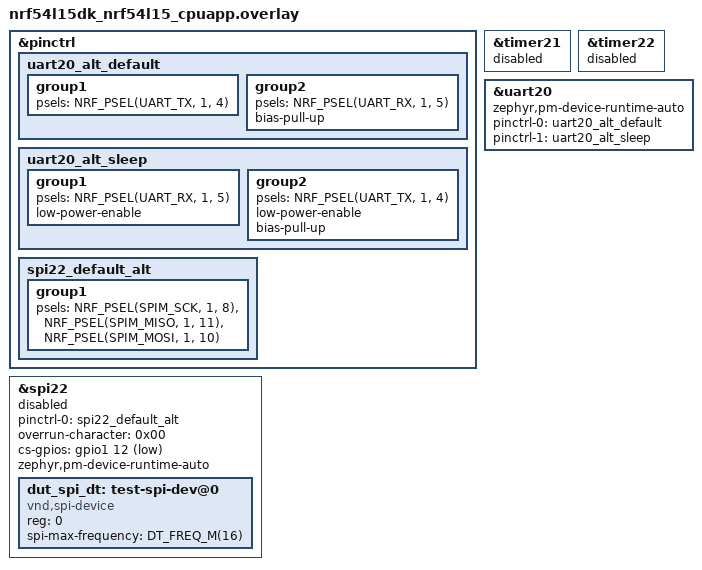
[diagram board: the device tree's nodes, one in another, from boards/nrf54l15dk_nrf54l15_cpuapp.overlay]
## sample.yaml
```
sample:
  description: Sample showing PPI sequencer
  name: PPI sequencer sample
tests:
  sample.peripheral.ppi_seq:
    sysbuild: true
    build_only: true
    integration_platforms:
      - nrf54l15dk/nrf54l15/cpuapp
    platform_allow:
      - nrf54l15dk/nrf54l15/cpuapp
```

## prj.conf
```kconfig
CONFIG_NRF_SYS_EVENT=y
CONFIG_PPI_SEQ=y
CONFIG_NRFX_SPIM=y
CONFIG_NRFX_SAADC=y
CONFIG_SHELL=y
CONFIG_CPU_LOAD=y
CONFIG_HEAP_MEM_POOL_SIZE=4096

CONFIG_PM_DEVICE=y
CONFIG_PM_DEVICE_RUNTIME=y
CONFIG_LOG=n

CONFIG_PPI_TRACE=y
```

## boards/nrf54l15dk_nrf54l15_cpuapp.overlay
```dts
/*
 * Copyright (c) 2024 Nordic Semiconductor
 *
 * SPDX-License-Identifier: Apache-2.0
 */

&pinctrl {
	uart20_alt_default: uart20_alt_default {
		group1 {
			psels = <NRF_PSEL(UART_TX, 1, 4)>;
		};

		group2 {
			psels = <NRF_PSEL(UART_RX, 1, 5)>;
			bias-pull-up;
		};
	};

	uart20_alt_sleep: uart20_alt_sleep {
		group1 {
			psels = <NRF_PSEL(UART_RX, 1, 5)>;
			low-power-enable;
		};

		group2 {
			psels = <NRF_PSEL(UART_TX, 1, 4)>;
			low-power-enable;
			bias-pull-up;
		};
	};

	spi22_default_alt: spi22_default_alt {
		group1 {
			psels = <NRF_PSEL(SPIM_SCK, 1, 8)>,
				<NRF_PSEL(SPIM_MISO, 1, 11)>,
				<NRF_PSEL(SPIM_MOSI, 1, 10)>;
		};
	};
};

cnt_timer: &timer21 {
	status = "reserved";
};

trig_timer: &timer22 {
	status = "reserved";
};

sample_spi: &spi22 {
	status = "reserved";
	pinctrl-0 = <&spi22_default_alt>;
	pinctrl-names = "default";
	overrun-character = <0x00>;
	cs-gpios = <&gpio1 12 GPIO_ACTIVE_LOW>;
	zephyr,pm-device-runtime-auto;

	dut_spi_dt: test-spi-dev@0 {
		compatible = "vnd,spi-device";
		reg = <0>;
		spi-max-frequency = <DT_FREQ_M(16)>;
	};
};

&uart20 {
	zephyr,pm-device-runtime-auto;
	pinctrl-0 = <&uart20_alt_default>;
	pinctrl-1 = <&uart20_alt_sleep>;
};
```

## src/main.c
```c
/*
 * Copyright (c) 2025 Nordic Semiconductor ASA
 *
 * SPDX-License-Identifier: LicenseRef-Nordic-5-Clause
 */

#include "common.h"
#include <string.h>
#include <stdlib.h>
#include <zephyr/kernel.h>
#include <zephyr/shell/shell.h>
#include <zephyr/pm/device.h>
#include <zephyr/pm/device_runtime.h>
#include <zephyr/logging/log.h>
LOG_MODULE_REGISTER(ppi_seq);

struct ppi_seq_generic_config current_config = {
	.mode = PPI_SEQ_SAMPLE_GRTC,
	.notifier = PPI_SEQ_NOTIFIER_SYS_TIMER,
	.period = 1000,
	.batch_cnt = 16,
	.repeat = 4,
};

int stop_shell_uart(const struct shell *sh)
{
	static const struct device *uart = DEVICE_DT_GET(DT_CHOSEN(zephyr_shell_uart));
	int pm_cnt = 0;
	int rv;

	if (IS_ENABLED(CONFIG_PM_DEVICE_RUNTIME)) {
		enum pm_device_state state;

		/* Disable UART to reduce the current consumption. */
		do {
			rv = pm_device_state_get(uart, &state);
			if (rv < 0) {
				return rv;
			}
			if (state != PM_DEVICE_STATE_ACTIVE) {
				break;
			}
			pm_device_runtime_put(uart);
			pm_cnt++;
		} while (1);
	}

	return pm_cnt;
}

void restart_shell_uart(const struct shell *sh, int pm_cnt)
{
	static const struct device *uart = DEVICE_DT_GET(DT_CHOSEN(zephyr_shell_uart));

	if (IS_ENABLED(CONFIG_PM_DEVICE_RUNTIME)) {
		for (int i = 0; i < pm_cnt; i++) {
			pm_device_runtime_get(uart);
		}
	}
}

void print_generic_status(const struct shell *sh)
{
	shell_print(sh, "Current configuration:");
	shell_print(sh, "\tPeriod source method: %s",
		current_config.mode == PPI_SEQ_SAMPLE_RTC ? "RTC" :
		current_config.mode == PPI_SEQ_SAMPLE_GRTC ? "GRTC" : "TIMER");
	shell_print(sh, "\tBatch notifier: %s",
		current_config.notifier == PPI_SEQ_NOTIFIER_NRFX_TIMER ?
		"nrfx_timer" : "k_timer");
	shell_print(sh, "\tPeriod: %d us", current_config.period);
	shell_print(sh, "\tBatch count: %d", current_config.batch_cnt);
	shell_print(sh, "\tNumber of batches in the sequence: %d", current_config.repeat);
}

static int ppi_seq_status_handler(const struct shell *sh, size_t argc, char **argv)
{
	ARG_UNUSED(argc);
	ARG_UNUSED(argv);

	print_generic_status(sh);
	return 0;
}

static int config_mode_grtc_handler(const struct shell *sh, size_t argc, char **argv)
{
	ARG_UNUSED(argc);
	ARG_UNUSED(argv);
	ARG_UNUSED(sh);
	current_config.mode = PPI_SEQ_SAMPLE_GRTC;
	return 0;
}

static int config_mode_rtc_handler(const struct shell *sh, size_t argc, char **argv)
{
	ARG_UNUSED(argc);
	ARG_UNUSED(argv);
	ARG_UNUSED(sh);
	current_config.mode = PPI_SEQ_SAMPLE_RTC;
	return 0;
}

static int config_mode_timer_handler(const struct shell *sh, size_t argc, char **argv)
{
	ARG_UNUSED(argc);
	ARG_UNUSED(argv);
	ARG_UNUSED(sh);
	current_config.mode = PPI_SEQ_SAMPLE_TIMER;
	return 0;
}

static int config_notifier_k_timer_handler(const struct shell *sh, size_t argc, char **argv)
{
	ARG_UNUSED(argc);
	ARG_UNUSED(argv);
	ARG_UNUSED(sh);
	current_config.notifier = PPI_SEQ_NOTIFIER_SYS_TIMER;
	return 0;
}

static int config_notifier_nrfx_timer_handler(const struct shell *sh, size_t argc, char **argv)
{
	ARG_UNUSED(argc);
	ARG_UNUSED(argv);
	ARG_UNUSED(sh);
	current_config.notifier = PPI_SEQ_NOTIFIER_NRFX_TIMER;
	return 0;
}

static int config_period_handler(const struct shell *sh, size_t argc, char **argv)
{
	ARG_UNUSED(argc);
	ARG_UNUSED(sh);
	int rv = 0;

	current_config.period = shell_strtoul(argv[1], 0, &rv);

	return rv;
}

static int config_batch_handler(const struct shell *sh, size_t argc, char **argv)
{
	ARG_UNUSED(argc);
	ARG_UNUSED(sh);
	int rv = 0;

	current_config.batch_cnt = shell_strtoul(argv[1], 0, &rv);

	return rv;
}

static int config_repeat_handler(const struct shell *sh, size_t argc, char **argv)
{
	ARG_UNUSED(argc);
	ARG_UNUSED(sh);
	int rv = 0;

	current_config.repeat = shell_strtoul(argv[1], 0, &rv);

	return rv;
}

struct ppi_seq_generic_config *get_generic_config(void)
{
	return &current_config;
}

SHELL_SUBCMD_ADD((ppi_sequence, config), repeat, NULL, "Number of batches in the sequence",
		config_repeat_handler, 2, 0);
SHELL_SUBCMD_ADD((ppi_sequence, config), batch_count, NULL, "Number of periods in a batch",
		config_batch_handler, 2, 0);
SHELL_SUBCMD_ADD((ppi_sequence, config), period, NULL, "Period (in microseconds)",
		config_period_handler, 2, 0);

SHELL_SUBCMD_ADD((ppi_sequence, config, notifier), k_timer, NULL,
		"Configure k_timer notifier\n", config_notifier_k_timer_handler, 1, 0);
SHELL_SUBCMD_ADD((ppi_sequence, config, notifier), nrfx_timer, NULL,
		"Configure nrfx_timer notifier\n", config_notifier_nrfx_timer_handler, 1, 0);
SHELL_SUBCMD_SET_CREATE(config_notifier_cmd, (ppi_sequence, config, notifier));
SHELL_SUBCMD_ADD((ppi_sequence, config), notifier, &config_notifier_cmd, "Notifier method",
		NULL, 1, 0);

SHELL_SUBCMD_ADD((ppi_sequence, config, mode), grtc, NULL,
		"Configure RTC mode\n", config_mode_grtc_handler, 1, 0);
SHELL_SUBCMD_ADD((ppi_sequence, config, mode), rtc, NULL,
		"Configure RTC mode\n", config_mode_rtc_handler, 1, 0);
SHELL_SUBCMD_ADD((ppi_sequence, config, mode), timer, NULL,
		"Configure TIMER mode\n", config_mode_timer_handler, 1, 0);
SHELL_SUBCMD_SET_CREATE(config_mode_cmd, (ppi_sequence, config, mode));
SHELL_SUBCMD_ADD((ppi_sequence, config), mode, &config_mode_cmd, "Peripheral used for period",
		NULL, 1, 0);
SHELL_SUBCMD_SET_CREATE(config_cmds, (ppi_sequence, config));
SHELL_SUBCMD_ADD((ppi_sequence), config, &config_cmds,
		"Print configuration (no arguments) or configure specific parameter",
		ppi_seq_status_handler, 1, 0);
SHELL_SUBCMD_SET_CREATE(ppi_sequence_cmd, (ppi_sequence));
SHELL_CMD_REGISTER(ppi_sequence, &ppi_sequence_cmd,
		   "SPI/SAADC operations using software and PPI sequencer", NULL);

int main(void)
{
	printk("PPI Sequencer for SPI transfers\n");

	DBG_PIN_CFG();

	return 0;
}
```

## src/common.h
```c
/*
 * Copyright (c) 2025 Nordic Semiconductor ASA
 *
 * SPDX-License-Identifier: LicenseRef-Nordic-5-Clause
 */

#ifndef COMMON_H__
#define COMMON_H__

#include <hal/nrf_gpio.h>
#include <drivers/ppi_seq.h>
#include <zephyr/shell/shell.h>
#include <zephyr/debug/cpu_load.h>
#include <zephyr/logging/log.h>

#ifdef __cplusplus
extern "C" {
#endif

#define USE_DBG_PIN 1

#if USE_DBG_PIN
#define DBG_PIN (2 * 32 + 10)
#define DBG_PIN_TOGGLE() do { \
	nrf_gpio_pin_set(DBG_PIN); \
	k_busy_wait(10); \
	nrf_gpio_pin_clear(DBG_PIN); \
} while (0)

#define DBG_PIN_CFG() nrf_gpio_cfg_output(DBG_PIN)
#else
#define DBG_PIN_TOGGLE()
#define DBG_PIN_CFG()
#endif

enum ppi_seq_sample_mode {
	PPI_SEQ_SAMPLE_GRTC,
	PPI_SEQ_SAMPLE_RTC,
	PPI_SEQ_SAMPLE_TIMER,
};

struct ppi_seq_generic_config {
	enum ppi_seq_sample_mode mode;
	enum ppi_seq_notifier_type notifier;
	uint32_t period;
	uint32_t repeat;
	uint32_t batch_cnt;
};

int stop_shell_uart(const struct shell *sh);
void restart_shell_uart(const struct shell *sh, int pm_cnt);
struct ppi_seq_generic_config *get_generic_config(void);
void print_generic_status(const struct shell *sh);

#ifdef __cplusplus
}
#endif


#endif /* COMMON_H__ */
```

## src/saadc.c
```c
/*
 * Copyright (c) 2025 Nordic Semiconductor ASA
 *
 * SPDX-License-Identifier: LicenseRef-Nordic-5-Clause
 */

#include "common.h"
#include <errno.h>
#include <string.h>
#include <stdlib.h>
#include <zephyr/kernel.h>
#include <zephyr/drivers/pinctrl.h>
#include <nrfx_gpiote.h>
#include <nrfx_saadc.h>
#include <zephyr/drivers/gpio/gpio_nrf.h>
LOG_MODULE_DECLARE(ppi_seq);

#define SAADC_NODE DT_NODELABEL(adc)

static NRF_TIMER_Type *trig_timer = (NRF_TIMER_Type *)DT_REG_ADDR(DT_NODELABEL(trig_timer));
#ifdef CONFIG_SOC_NRF54L15_CPUAPP
static const void *rtc_reg = (void *)0x50105000;
#endif

static struct k_sem sem;
static uint32_t repeat_cnt;
static uint32_t buf_idx;
static nrf_saadc_value_t *manual_buffers[2];
static struct ppi_seq seq;
static struct ppi_seq_config seq_config;
static struct ppi_seq_notifier notifier;

static struct ppi_seq_generic_config *curr_cfg;

static int saadc_init(void)
{
	IRQ_CONNECT(DT_IRQN(SAADC_NODE), DT_IRQ_BY_IDX(SAADC_NODE, 0, priority),
			nrfx_saadc_irq_handler, NULL, 0);

	return nrfx_saadc_init(0);
}

static void saadc_uninit(uint32_t ch_mask)
{
	nrfx_saadc_channels_deconfig(ch_mask);
	nrfx_saadc_uninit();
}

static void saadc_event_handler(nrfx_saadc_evt_t const *event)
{
	int rv;

	switch (event->type) {
	case NRFX_SAADC_EVT_DONE:
		repeat_cnt--;
		break;
	case NRFX_SAADC_EVT_FINISHED:
		k_sem_give(&sem);
		break;
	case NRFX_SAADC_EVT_BUF_REQ:
		if (repeat_cnt > 1) {
			rv = nrfx_saadc_buffer_set(manual_buffers[buf_idx], curr_cfg->batch_cnt);
			buf_idx = buf_idx == 0 ? 1 : 0;
		}
		break;
	default:
		break;
	}
}

static int manual_run(const struct shell *sh, struct ppi_seq_generic_config *config, int *load)
{
	int rv;
	nrfx_saadc_channel_t channel_config =
		NRFX_SAADC_DEFAULT_CHANNEL_SE(NRFX_ANALOG_EXTERNAL_AIN4, 0);
	uint32_t total = config->batch_cnt * config->repeat * config->period;
	nrfx_saadc_adv_config_t saadc_config = {
		.oversampling = NRF_SAADC_OVERSAMPLE_DISABLED,
		.burst = NRF_SAADC_BURST_DISABLED,
		.internal_timer_cc = 0,
		.start_on_end = true,
	};
	nrfx_gppi_handle_t gppi_handle;
	nrfx_timer_config_t timer_config = {
		.frequency = MHZ(1),
		.mode = NRF_TIMER_MODE_TIMER,
		.bit_width = NRF_TIMER_BIT_WIDTH_32,
		.p_context = NULL
	};
	nrfx_timer_t timer = {};
	uint32_t ch_mask = BIT(0);
	uint32_t evt_timer = 0, task_saadc = 0;
	uint32_t t = 0;

	/* Initialize TIMER that will be sampling SAADC. */
	timer.p_reg = trig_timer;
	rv = nrfx_timer_init(&timer, &timer_config, NULL);
	if (rv < 0) {
		shell_error(sh, "Failed to initialize the sampling TIMER:%d", rv);
		goto finalize;
	}
	nrfx_timer_extended_compare(&timer, 0, config->period,
			NRF_TIMER_SHORT_COMPARE0_CLEAR_MASK, false);

	/* Setup PPI connection between TIMER and SAADC. */
	task_saadc = nrf_saadc_task_address_get(NRF_SAADC, NRF_SAADC_TASK_SAMPLE);
	evt_timer = nrfx_timer_event_address_get(&timer, nrf_timer_compare_event_get(0));
	rv = nrfx_gppi_conn_alloc(evt_timer, task_saadc, &gppi_handle);
	if (rv < 0) {
		shell_error(sh, "Failed to allocate PPI connection:%d", rv);
		goto finalize;
	}
	nrfx_gppi_conn_enable(gppi_handle);

	/* Prepare buffers for SAADC. */
	manual_buffers[0] = malloc(config->batch_cnt * sizeof(nrf_saadc_value_t));
	manual_buffers[1] = malloc(config->batch_cnt * sizeof(nrf_saadc_value_t));

	memset(manual_buffers[0], 0xaa, config->batch_cnt * sizeof(nrf_saadc_value_t));
	memset(manual_buffers[1], 0xaa, config->batch_cnt * sizeof(nrf_saadc_value_t));
	channel_config.channel_config.acq_time = 10 * 8 - 1;
	rv = nrfx_saadc_channels_config(&channel_config, ch_mask);
	if (rv < 0) {
		shell_error(sh, "Failed to configure the SAADC channel:%d", rv);
		goto finalize;
	}

	rv = nrfx_saadc_advanced_mode_set(ch_mask, NRF_SAADC_RESOLUTION_10BIT,
			&saadc_config, saadc_event_handler);
	if (rv < 0) {
		shell_error(sh, "Failed to configure the SAADC:%d", rv);
		goto finalize;
	}

	buf_idx = 1;
	rv = nrfx_saadc_buffer_set(manual_buffers[0], config->batch_cnt);
	if (rv < 0) {
		shell_error(sh, "Failed to set SAADC buffer:%d", rv);
		goto finalize;
	}

	k_sem_init(&sem, 0, 1);
	repeat_cnt = config->repeat;
	rv = nrfx_saadc_mode_trigger();
	if (rv < 0) {
		shell_error(sh, "Failed to trigger SAADC:%d", rv);
		goto finalize;
	}

	DBG_PIN_TOGGLE();
	if (IS_ENABLED(CONFIG_CPU_LOAD)) {
		(void)cpu_load_get(true);
	}
	t = k_cycle_get_32();
	nrfx_timer_enable(&timer);

	rv = k_sem_take(&sem, K_USEC(total + 10000));
	if (rv < 0) {
		shell_error(sh, "Failed to complete the manual run on time:%d", rv);
		goto finalize;
	}
	t = k_cycle_get_32() - t;
	if (IS_ENABLED(CONFIG_CPU_LOAD)) {
		*load = cpu_load_get(true);
	}
	DBG_PIN_TOGGLE();

finalize:
	if (rv < 0) shell_error(sh, "eee:%d", rv);
	nrfx_timer_disable(&timer);
	nrfx_timer_uninit(&timer);
	nrfx_gppi_conn_disable(gppi_handle);
	nrfx_gppi_conn_free(evt_timer, task_saadc, gppi_handle);

	free(manual_buffers[0]);
	free(manual_buffers[1]);
	return rv < 0 ? rv : t;
}

static void saadc_ppi_seq_cb(struct ppi_seq *ppi_seq, bool last)
{
	if (last) {
		k_sem_give(&sem);
	}
}

static nrfx_gppi_handle_t gppi_saadc_started_sample;
static nrfx_gppi_handle_t gppi_saadc_end_stop;

static int initialize_ppi_seq(const struct shell *sh, struct ppi_seq_generic_config *config)
{
	uint32_t evt_end = nrf_saadc_event_address_get(NRF_SAADC, NRF_SAADC_EVENT_END);
	uint32_t evt_started = nrf_saadc_event_address_get(NRF_SAADC, NRF_SAADC_EVENT_STARTED);
	uint32_t task_start = nrf_saadc_task_address_get(NRF_SAADC, NRF_SAADC_TASK_START);
	uint32_t task_sample = nrf_saadc_task_address_get(NRF_SAADC, NRF_SAADC_TASK_SAMPLE);
	uint32_t task_stop = nrf_saadc_task_address_get(NRF_SAADC, NRF_SAADC_TASK_STOP);
	int rv;

	rv = nrfx_gppi_conn_alloc(evt_started, task_sample, &gppi_saadc_started_sample);
	if (rv < 0) {
		return rv;
	}
	nrfx_gppi_conn_enable(gppi_saadc_started_sample);

	rv = nrfx_gppi_conn_alloc(evt_end, task_stop, &gppi_saadc_end_stop);
	if (rv < 0) {
		return rv;
	}
	nrfx_gppi_conn_enable(gppi_saadc_end_stop);

	notifier.type = config->notifier;
	if (notifier.type == PPI_SEQ_NOTIFIER_SYS_TIMER) {
		notifier.sys_timer.offset = 10;
	} else {
		notifier.nrfx_timer.timer.p_reg =
			(NRF_TIMER_Type *)DT_REG_ADDR(DT_NODELABEL(cnt_timer));
		notifier.nrfx_timer.end_seq_event = evt_end;
		notifier.nrfx_timer.extra_main_ops = 0;
	}

	seq_config.notifier = &notifier;
	if (config->mode == PPI_SEQ_SAMPLE_GRTC) {
		seq_config.timer_reg = NULL;
		seq_config.rtc = NULL;
		seq_config.use_grtc = true;
	} else if (config->mode == PPI_SEQ_SAMPLE_RTC) {
		seq_config.timer_reg = NULL;
		seq_config.rtc = (void *)rtc_reg;
		seq_config.use_grtc = false;
	} else {
		seq_config.timer_reg = trig_timer;
		seq_config.rtc = NULL;
		seq_config.use_grtc = false;
	}

	seq_config.extra_ops = NULL;
	seq_config.extra_ops_count = 0;

	seq_config.callback = saadc_ppi_seq_cb;
	seq_config.task = task_start;

	return ppi_seq_init(&seq, &seq_config);
}

static void uninit_ppi_seq(void)
{
	ppi_seq_uninit(&seq);
	uint32_t evt_started = nrf_saadc_event_address_get(NRF_SAADC, NRF_SAADC_EVENT_STARTED);
	uint32_t task_sample = nrf_saadc_task_address_get(NRF_SAADC, NRF_SAADC_TASK_SAMPLE);
	uint32_t evt_end = nrf_saadc_event_address_get(NRF_SAADC, NRF_SAADC_EVENT_END);
	uint32_t task_stop = nrf_saadc_task_address_get(NRF_SAADC, NRF_SAADC_TASK_STOP);

	nrfx_gppi_conn_disable(gppi_saadc_started_sample);
	nrfx_gppi_conn_disable(gppi_saadc_end_stop);
	nrfx_gppi_conn_free(evt_started, task_sample, gppi_saadc_started_sample);
	nrfx_gppi_conn_free(evt_end, task_stop, gppi_saadc_end_stop);
}

static int seq_run(const struct shell *sh, struct ppi_seq_generic_config *config, int *load)
{
	int rv;
	nrfx_saadc_channel_t channel_config =
		NRFX_SAADC_DEFAULT_CHANNEL_SE(NRFX_ANALOG_EXTERNAL_AIN4, 0);
	uint32_t total = config->batch_cnt * config->repeat * config->period;
	uint32_t ch_mask = BIT(0);
	nrfx_saadc_adv_config_t saadc_config = {
		.oversampling = NRF_SAADC_OVERSAMPLE_DISABLED,

		.burst = NRF_SAADC_BURST_DISABLED,
		.internal_timer_cc = 0,
		.start_on_end = true,
	};
	uint32_t t = 0;

	manual_buffers[0] = malloc(config->batch_cnt * sizeof(nrf_saadc_value_t));
	manual_buffers[1] = malloc(config->batch_cnt * sizeof(nrf_saadc_value_t));
	memset(manual_buffers[0], 0xaa, config->batch_cnt * sizeof(nrf_saadc_value_t));
	memset(manual_buffers[1], 0xaa, config->batch_cnt * sizeof(nrf_saadc_value_t));

	channel_config.channel_config.acq_time = 10 * 8 - 1;
	rv = nrfx_saadc_channels_config(&channel_config, ch_mask);
	if (rv < 0) {
		shell_error(sh, "Failed to configure the SAADC channel:%d", rv);
		goto finalize;
	}

	rv = nrfx_saadc_advanced_mode_set(ch_mask, NRF_SAADC_RESOLUTION_10BIT,
			&saadc_config, NULL);
	if (rv < 0) {
		shell_error(sh, "Failed to configure the SAADC:%d", rv);
		goto finalize;
	}

	buf_idx = 1;
	nrf_saadc_buffer_init(NRF_SAADC, manual_buffers[0], 1);
	nrf_saadc_enable(NRF_SAADC);
	*(uint32_t *)((uint32_t)NRF_SAADC + 0x63c) = 1;
	NRF_SAADC->EVENTS_STARTED=0;
	NRF_SAADC->EVENTS_DONE=0;
	NRF_SAADC->EVENTS_END=0;

	k_sem_init(&sem, 0, 1);
	repeat_cnt = config->repeat;

	DBG_PIN_TOGGLE();
	if (IS_ENABLED(CONFIG_CPU_LOAD)) {
		(void)cpu_load_get(true);
	}
	t = k_cycle_get_32();
	rv = ppi_seq_start(&seq, config->period, config->batch_cnt, config->repeat);
	if (rv < 0) {
		shell_error(sh, "Failed to trigger SAADC:%d", rv);
		goto finalize;
	}

	rv = k_sem_take(&sem, K_USEC(total + 10000));
	if (rv < 0) {
		shell_error(sh, "Failed to complete the PPI sequencer run on time:%d", rv);
		goto finalize;
	}
	t = k_cycle_get_32() - t;
	if (IS_ENABLED(CONFIG_CPU_LOAD)) {
		*load = cpu_load_get(true);
	}
	DBG_PIN_TOGGLE();

	printk("saadc evts: started:%d done:%d end:%d\n",
		NRF_SAADC->EVENTS_STARTED,
		NRF_SAADC->EVENTS_DONE,
		NRF_SAADC->EVENTS_END);

finalize:
	uint8_t *buf =(uint8_t *)manual_buffers[0];
	for (int i = 0; i < curr_cfg->batch_cnt * sizeof(nrf_saadc_value_t); i++) {
		printk("%02x ", buf[i]);
	}
	printk("\n");
	printk("saadc: ptr:%08x buf:%08x\n", NRF_SAADC->RESULT.PTR, (uint32_t)manual_buffers[0]);
	free(manual_buffers[0]);
	free(manual_buffers[1]);
	return rv < 0 ? rv : t;
}

static void print_status(const struct shell *sh)
{
	print_generic_status(sh);
}

static int ppi_seq_run_handler(const struct shell *sh, size_t argc, char **argv)
{
	uint32_t pm_cnt = 0;
	int t_manual = 0, t_ppi = 0;
	int load = 0, load_ppi = 0;
	int rv;

	curr_cfg = get_generic_config();
	print_status(sh);

	rv = saadc_init();
	if (rv < 0) {
		goto finalize;
	}

	pm_cnt = stop_shell_uart(sh);

	if (argc > 1) {
		uint32_t t = shell_strtoul(argv[1], 0, &rv);
		for (int i = 0; i < 10; i++) {
			k_msleep(t);
		}
	}

	rv =  manual_run(sh, curr_cfg, &load);
	if (rv < 0) {
		goto finalize;
	}
	t_manual = rv;

	restart_shell_uart(sh, pm_cnt);
	uint8_t *buf =(uint8_t *)manual_buffers[0];
	for (int i = 0; i < curr_cfg->batch_cnt * sizeof(nrf_saadc_value_t); i++) {
		printk("%02x ", buf[i]);
	}
	printk("\n");
	free(manual_buffers[0]);
	pm_cnt = stop_shell_uart(sh);


	rv = initialize_ppi_seq(sh, curr_cfg);
	if (rv < 0) {
		goto finalize;
	}

	rv = seq_run(sh, curr_cfg, &load_ppi);
	if (rv < 0) {
		goto finalize;
	}
	t_ppi = rv;

finalize:
	restart_shell_uart(sh, pm_cnt);

	if (rv >= 0) {
		shell_print(sh, "- Manual operation:\n\tLOAD:%d.%d%%\n\ttook:%d us\n",
			load / 10, load % 10, t_manual);
		shell_print(sh, "- PPI Sequencer transfers:\n\tLOAD:%d.%d%%\n\ttook:%d us\n",
			load_ppi / 10, load_ppi % 10, t_ppi);
	} else if (rv == -ENOTSUP) {
		shell_error(sh, "Configuration not supported\n");
	} else {
		shell_error(sh, "Command failed with:%d\n", rv);
	}
	uninit_ppi_seq();
	saadc_uninit(BIT(0));
	return rv;
}

static int ppi_seq_status_handler(const struct shell *sh, size_t argc, char **argv)
{
	ARG_UNUSED(argc);
	ARG_UNUSED(argv);

	print_status(sh);

	return 0;
}

SHELL_SUBCMD_ADD((ppi_sequence), saadc_status, NULL, "Print current SPI configuration",
		ppi_seq_status_handler, 1, 0);
SHELL_SUBCMD_ADD((ppi_sequence), saadc_run, NULL,
		"Run SAADC sequence using the current configuration",
		ppi_seq_run_handler, 1, 1);
```

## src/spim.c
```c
/*
 * Copyright (c) 2025 Nordic Semiconductor ASA
 *
 * SPDX-License-Identifier: LicenseRef-Nordic-5-Clause
 */

#include "common.h"
#include <errno.h>
#include <string.h>
#include <stdlib.h>
#include <nrfx_gpiote.h>
#include <nrfx_spim.h>
#include <drivers/ppi_seq_i2c_spi.h>
#include <zephyr/kernel.h>
#include <zephyr/drivers/pinctrl.h>
#include <zephyr/drivers/gpio/gpio_nrf.h>
#include <zephyr/debug/cpu_load.h>
LOG_MODULE_DECLARE(ppi_seq);

#define SPI_FREQ MHZ(8)

#define SPIM_NODE DT_NODELABEL(sample_spi)
static nrfx_spim_t spim;
static NRF_TIMER_Type *trig_timer = (NRF_TIMER_Type *)DT_REG_ADDR(DT_NODELABEL(trig_timer));
static struct ppi_seq_i2c_spi seq_spim;
static struct ppi_seq_config seq_config;
static struct ppi_seq_notifier notifier;
static struct ppi_seq_extra_op extra_op;
static struct k_sem spi_sem;

#ifdef CONFIG_SOC_NRF54L15_CPUAPP
static const void *rtc_reg = (void *)0x50105000;
#endif

static uint32_t current_xfer_length = 8;
static uint32_t current_second_xfer_offset;

static int spim_init(void)
{
	int rv;
	nrfx_spim_config_t config;

	IRQ_CONNECT(DT_IRQN(SPIM_NODE), DT_IRQ_BY_IDX(SPIM_NODE, 0, priority),
			nrfx_spim_irq_handler, &spim, 0);

	spim.p_reg = (NRF_SPIM_Type *)DT_REG_ADDR(SPIM_NODE);

	PINCTRL_DT_DEFINE(SPIM_NODE);
	rv = pinctrl_apply_state(PINCTRL_DT_DEV_CONFIG_GET(SPIM_NODE), PINCTRL_STATE_DEFAULT);
	if (rv < 0) {
		LOG_ERR("SPI pinctrl initialization failed:%d", rv);
		return rv;
	}

	/* CS configure. */
	uint32_t pin = DT_GPIO_PIN(SPIM_NODE, cs_gpios);
	uint32_t port = DT_PROP(DT_GPIO_CTLR(SPIM_NODE, cs_gpios), port);
	uint32_t ss_pin = 32 * port + pin;

	nrf_gpio_pin_set(ss_pin);
	nrf_gpio_cfg_output(ss_pin);
	nrf_spim_csn_configure(spim.p_reg, ss_pin, NRF_SPIM_CSN_POL_LOW, 16);

	config.ss_pin = NRF_SPIM_PIN_NOT_CONNECTED;
	config.frequency = SPI_FREQ;
	config.mode = NRF_SPIM_MODE_0;
	config.use_hw_ss = true;
	config.rx_delay = 1;
	config.bit_order = NRF_SPIM_BIT_ORDER_MSB_FIRST;
	config.skip_gpio_cfg = true;
	config.skip_psel_cfg = true;

	rv = nrfx_spim_init(&spim, &config, NULL, NULL);
	if (rv < 0) {
		LOG_ERR("Failed to initialize nrfx_spim instance %d", rv);
	}

	return rv;
}

static void spim_uninit(void)
{
	NRF_SPIM_Type *spim_reg = (NRF_SPIM_Type *)DT_REG_ADDR(SPIM_NODE);
	uint32_t pin = DT_GPIO_PIN(SPIM_NODE, cs_gpios);
	uint32_t port = DT_PROP(DT_GPIO_CTLR(SPIM_NODE, cs_gpios), port);
	uint32_t ss_pin = 32 * port + pin;

	nrfx_spim_uninit(&spim);

	nrf_gpio_cfg_default(nrf_spim_miso_pin_get(spim_reg));
	nrf_gpio_cfg_default(nrf_spim_mosi_pin_get(spim_reg));
	nrf_gpio_cfg_default(nrf_spim_sck_pin_get(spim_reg));
	nrf_gpio_cfg_default(ss_pin);
	nrf_spim_csn_configure(spim.p_reg, NRF_SPIM_PIN_NOT_CONNECTED, NRF_SPIM_CSN_POL_LOW, 0);
}

static int initialize_single_xfer(const struct shell *sh, struct ppi_seq_generic_config *config)
{
	notifier.type = config->notifier;
	if (notifier.type == PPI_SEQ_NOTIFIER_SYS_TIMER) {
		notifier.sys_timer.offset = (1000000 * current_xfer_length) / (SPI_FREQ / 8) + 10;
	} else {
		notifier.nrfx_timer.timer.p_reg =
			(NRF_TIMER_Type *)DT_REG_ADDR(DT_NODELABEL(cnt_timer));
		notifier.nrfx_timer.end_seq_event = nrfx_spim_end_event_address_get(&spim);
		notifier.nrfx_timer.extra_main_ops = (current_second_xfer_offset != 0) ? 1 : 0;
	}

	seq_config.notifier = &notifier;
	if (config->mode == PPI_SEQ_SAMPLE_GRTC) {
		seq_config.timer_reg = NULL;
		seq_config.rtc = NULL;
		seq_config.use_grtc = true;
	} else if (config->mode == PPI_SEQ_SAMPLE_RTC) {
		seq_config.timer_reg = NULL;
		seq_config.rtc = (void *)rtc_reg;
		seq_config.use_grtc = false;
	} else {
		seq_config.timer_reg = trig_timer;
		seq_config.rtc = NULL;
		seq_config.use_grtc = (current_second_xfer_offset != 0);
	}

	if (current_second_xfer_offset != 0) {
		extra_op.task = nrfx_spim_start_task_address_get(&spim);
		extra_op.offset = current_second_xfer_offset;
		seq_config.extra_ops = &extra_op;
		seq_config.extra_ops_count = 1;
		if (config->mode == PPI_SEQ_SAMPLE_GRTC) {
			shell_error(sh, "Double transfer batch does not support GRTC only, "
					"requires RTC or TIMER");
			return -ENOTSUP;
		}
	} else {
		seq_config.extra_ops = NULL;
		seq_config.extra_ops_count = 0;
	}

	seq_config.callback = ppi_seq_spim_internal_cb;
	seq_config.task = nrfx_spim_start_task_address_get(&spim);
	seq_spim.spim = &spim;

	return ppi_seq_spim_init(&seq_spim, &seq_config);
}

static void uninitialize(void)
{
	ppi_seq_spim_uninit(&seq_spim);
	spim_uninit();
}

static void ppi_seq_spim_cb(struct ppi_seq_spim *engine, struct ppi_seq_spim_data *data,
		bool last)
{
	NRF_P2->OUTSET=BIT(8);
	if (last) {
		k_sem_give(&spi_sem);
	}
	NRF_P2->OUTCLR=BIT(8);
}

static int perform_single_xfer_set(struct ppi_seq_generic_config *config,
				   uint32_t timeout, int *load)
{
	uint8_t *bufs[4];
	uint32_t t;
	int rv;

	for (int i = 0; i < ARRAY_SIZE(bufs); i++) {
		bufs[i] = malloc(current_xfer_length * config->batch_cnt);
		if (bufs[i] == NULL) {
			return -ENOMEM;
		}
		for (int j = 0; j < current_xfer_length * config->batch_cnt; j++) {
			bufs[i][j] = j % current_xfer_length;
		}
	}

	struct ppi_seq_spim_job job = {
		.desc = {
			.p_tx_buffer = bufs[0],
			.tx_length = current_xfer_length,
			.p_rx_buffer = bufs[1],
			.rx_length = current_xfer_length,
		},
		.tx_second_buf = bufs[2],
		.rx_second_buf = bufs[3],
		.batch_cnt = config->batch_cnt,
		.extra_xfers = (current_second_xfer_offset != 0) ? 1 : 0,
		.repeat = config->repeat,
		.tx_postinc = true,
		.cb = ppi_seq_spim_cb
	};

	k_sem_init(&spi_sem, 0, 1);

	DBG_PIN_TOGGLE();
	if (IS_ENABLED(CONFIG_CPU_LOAD)) {
		(void)cpu_load_get(true);
	}
	t = k_cycle_get_32();

	rv = ppi_seq_spim_start(&seq_spim, config->period, &job);
	if (rv < 0) {
		return rv;
	}

	rv = k_sem_take(&spi_sem, K_USEC(timeout));
	if (rv < 0) {
		return rv;
	}

	t = k_cycle_get_32() - t;
	*load = cpu_load_get(true);
	DBG_PIN_TOGGLE();

	for (int i = 0; i < ARRAY_SIZE(bufs); i++) {
		free(bufs[i]);
	}

	return t;
}

struct manual_xfer_data {
	struct k_timer timer;
	nrfx_spim_xfer_desc_t desc;
	uint32_t xfer_cnt;
	bool do_sem;
};

static void timeout_handler(struct k_timer *timer)
{
	struct manual_xfer_data *data = k_timer_user_data_get(timer);

	nrfx_spim_xfer(&spim, &data->desc, 0);
	data->xfer_cnt--;
	if (data->xfer_cnt == 0) {
		k_timer_stop(timer);
		if (data->do_sem) {
			k_sem_give(&spi_sem);
		}
	}
}

static int manual_xfer(struct ppi_seq_generic_config *config, int *load)
{
	uint8_t *tx_buf = malloc(current_xfer_length);
	uint8_t *rx_buf = malloc(current_xfer_length);
	struct manual_xfer_data test_data;
	struct manual_xfer_data test_data2;
	nrfx_spim_xfer_desc_t desc = {
		.p_tx_buffer = tx_buf,
		.tx_length = sizeof(current_xfer_length),
		.p_rx_buffer = rx_buf,
		.rx_length = sizeof(current_xfer_length),
	};
	uint32_t total_time = config->period * config->batch_cnt * config->repeat;
	uint32_t t;
	int rv;

	k_timer_init(&test_data.timer, timeout_handler, NULL);
	k_timer_user_data_set(&test_data.timer, &test_data);

	test_data.desc = desc;
	if (current_second_xfer_offset) {
		test_data2.desc = desc;
		test_data2.xfer_cnt = (config->batch_cnt / 2) * config->repeat;
		test_data.xfer_cnt = (config->batch_cnt / 2) * config->repeat;
		test_data2.do_sem = true;
		test_data.do_sem = false;
		k_timer_init(&test_data2.timer, timeout_handler, NULL);
		k_timer_user_data_set(&test_data2.timer, &test_data2);
	} else {
		test_data.xfer_cnt = config->batch_cnt * config->repeat;
		test_data.do_sem = true;
	}

	for (int i = 0; i < current_xfer_length; i++) {
		tx_buf[i] = i;
	}

	k_sem_init(&spi_sem, 0, 1);
	DBG_PIN_TOGGLE();
	if (IS_ENABLED(CONFIG_CPU_LOAD)) {
		(void)cpu_load_get(true);
	}
	t = k_cycle_get_32();
	k_timer_start(&test_data.timer, K_USEC(config->period), K_USEC(config->period));
	if (current_second_xfer_offset) {
		k_timer_start(&test_data2.timer, K_USEC(config->period + current_second_xfer_offset),
						K_USEC(config->period));
	}

	rv = k_sem_take(&spi_sem, K_USEC(total_time + 10000));
	if (rv < 0) {
		return rv;
	}

	t = k_cycle_get_32() - t;
	if (IS_ENABLED(CONFIG_CPU_LOAD)) {
		*load = cpu_load_get(true);
	}
	DBG_PIN_TOGGLE();
	free(tx_buf);
	free(rx_buf);
	return t;
}

static int run(const struct shell *sh, struct ppi_seq_generic_config *config)
{
	int rv;
	int t_manual = 0, t_ppi = 0;
	int load = 0, load_ppi = 0;
	int total = config->repeat * config->batch_cnt;
	int pm_cnt;
	int line = 0;

	rv = spim_init();
	if (rv < 0) {
		shell_error(sh, "Failed to initialize SPIM");
		return rv;
	}

	if (current_second_xfer_offset != 0) {
		shell_print(sh, "Performing %d SPI transfers (engine callback every %d transfers)"
			" with %d us sleep period, 2 transfers per period (seconds after %d us)",
			total, config->batch_cnt, config->period, current_second_xfer_offset);
		total /= 2;
	} else {
		shell_print(sh, "Performing %d SPI transfers (engine callback every %d transfers)"
			" with %d us sleep period", total, config->batch_cnt, config->period);
	}
	shell_print(sh, "Transfers should take: %d us\n", (total - 1) * config->period);

	/* Ensure that all is printed as uart is forced to be off. */
	k_msleep(1);
	pm_cnt = stop_shell_uart(sh);
	k_msleep(100);

	rv = manual_xfer(config, &load);
	if (rv < 0) {
		line = __LINE__;
		goto finalize;
	}
	t_manual = rv;

	rv = initialize_single_xfer(sh, config);
	if (rv < 0) {
		line = __LINE__;
		goto finalize;
	}

	rv = perform_single_xfer_set(config, config->period * (total + 1) + 1000, &load_ppi);
	if (rv < 0) {
		line = __LINE__;
		goto finalize;
	}
	t_ppi = rv;
	uninitialize();

finalize:
	restart_shell_uart(sh, pm_cnt);

	if (rv >= 0) {
		shell_print(sh, "- Manual transfers:\n\tLOAD:%d.%d%%\n\ttook:%d us\n",
			load / 10, load % 10, t_manual);
		shell_print(sh, "- PPI Sequencer transfers:\n\tLOAD:%d.%d%%\n\ttook:%d us\n",
			load_ppi / 10, load_ppi % 10, t_ppi);
	} else if (rv == -ENOTSUP) {
		shell_error(sh, "Configuration not supported\n");
	} else {
		shell_error(sh, "Command failed with:%d line:%d\n", rv, line);
	}

	return rv;
}

static void print_status(const struct shell *sh)
{
	print_generic_status(sh);
	shell_print(sh, "\tTransfer length: %d", current_xfer_length);
	if (current_second_xfer_offset != 0) {
		shell_print(sh, "\tSecond transfer in the sequence after: %d us",
				current_second_xfer_offset);
	}
}

static int ppi_seq_status_handler(const struct shell *sh, size_t argc, char **argv)
{
	ARG_UNUSED(argc);
	ARG_UNUSED(argv);

	print_status(sh);

	return 0;
}

static int ppi_seq_run_handler(const struct shell *sh, size_t argc, char **argv)
{
	ARG_UNUSED(argc);
	ARG_UNUSED(argv);

	print_status(sh);

	return run(sh, get_generic_config());
}

static int config_xfer_length_handler(const struct shell *sh, size_t argc, char **argv)
{
	ARG_UNUSED(argc);
	ARG_UNUSED(sh);
	int rv = 0;

	current_xfer_length = shell_strtoul(argv[1], 0, &rv);

	return rv;
}

static int config_2nd_xfer_handler(const struct shell *sh, size_t argc, char **argv)
{
	ARG_UNUSED(argc);
	ARG_UNUSED(sh);
	int rv = 0;

	current_second_xfer_offset = shell_strtoul(argv[1], 0, &rv);

	return rv;
}

SHELL_SUBCMD_ADD((ppi_sequence, config), spi_second_xfer_offset, NULL,
		"Offset (in microseconds) for second transfer in the sequence "
		"(0 for single transfer per period)",
		config_2nd_xfer_handler, 2, 0);
SHELL_SUBCMD_ADD((ppi_sequence, config), spi_xfer_length, NULL, "Transfer length",
		config_xfer_length_handler, 2, 0);

SHELL_SUBCMD_ADD((ppi_sequence), spi_run, NULL, "Run SPI sequence using the current configuration",
		ppi_seq_run_handler, 1, 0);
SHELL_SUBCMD_ADD((ppi_sequence), spi_status, NULL, "Print current SPI configuration",
		ppi_seq_status_handler, 1, 0);
```
